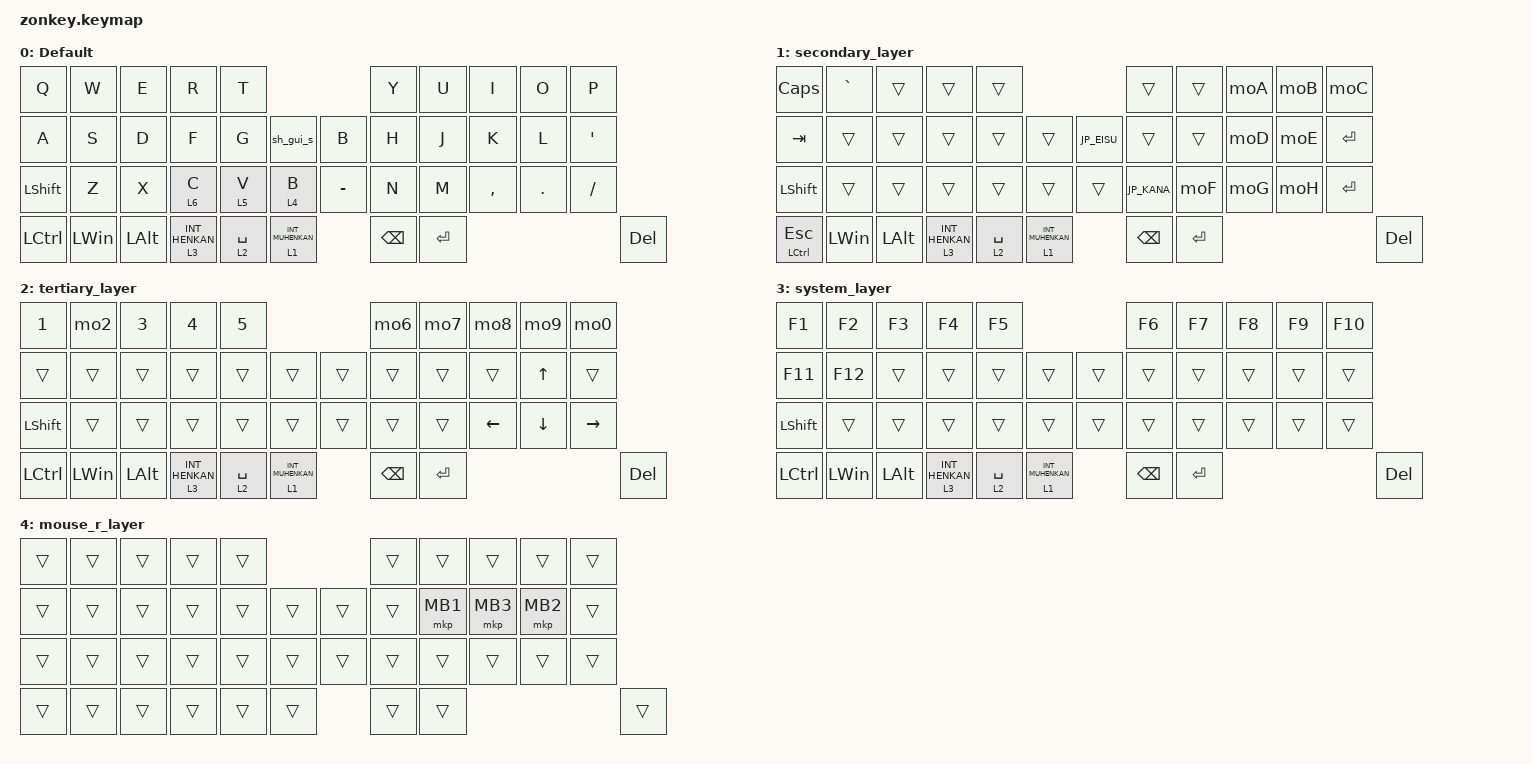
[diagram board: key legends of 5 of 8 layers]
#include <input/processors.dtsi>
#include <behaviors.dtsi>
#include <dt-bindings/zmk/bt.h>
#include <dt-bindings/zmk/keys.h>
#include <dt-bindings/zmk/outputs.h>
#include <dt-bindings/zmk/pointing.h>

#define DEFAULT_LAYER   0
#define SECONDARY_LAYER 1
#define TERTIARY_LAYER  2
#define SYSTEM_LAYER    3
#define MOUSE_R_LAYER   4
#define SCROLL_R_LAYER  5
#define MOUSE_L_LAYER   6
#define SCROLL_L_LAYER  7

// Mouse Scroll Value
#define ZMK_POINTING_DEFAULT_SCRL_VAL 100

// cirque trackpad input&layer control
&glidepoint_listener_R {
    input-processors =
        <&zip_xy_transform (INPUT_TRANSFORM_XY_SWAP | INPUT_TRANSFORM_X_INVERT | INPUT_TRANSFORM_Y_INVERT)>,
        <&zip_xy_scaler 3 2>,
        <&zip_temp_layer MOUSE_R_LAYER 300>;

    lowspeedmode {
        layers = <SECONDARY_LAYER>;
        input-processors =
            <&zip_xy_transform (INPUT_TRANSFORM_XY_SWAP | INPUT_TRANSFORM_X_INVERT | INPUT_TRANSFORM_Y_INVERT)>,
            <&zip_xy_scaler 3 5>,
            <&zip_temp_layer MOUSE_R_LAYER 300>;
    };

    scroller {
        layers = <SCROLL_R_LAYER>;
        input-processors =
            <&zip_xy_to_scroll_mapper>,
            <&zip_scroll_transform (INPUT_TRANSFORM_XY_SWAP | INPUT_TRANSFORM_Y_INVERT)>,
            <&zip_scroll_scaler 1 32>;
    };
};

&glidepoint_listener_L {
    input-processors =
        <&zip_xy_transform (INPUT_TRANSFORM_XY_SWAP | INPUT_TRANSFORM_X_INVERT | INPUT_TRANSFORM_Y_INVERT)>,
        <&zip_xy_scaler 3 2>,
        <&zip_temp_layer MOUSE_L_LAYER 300>;

    lowspeedmode {
        layers = <TERTIARY_LAYER>;
        input-processors =
            <&zip_xy_transform (INPUT_TRANSFORM_XY_SWAP | INPUT_TRANSFORM_X_INVERT | INPUT_TRANSFORM_Y_INVERT)>,
            <&zip_xy_scaler 3 4>,
            <&zip_temp_layer MOUSE_L_LAYER 300>;
    };

    scroller {
        layers = <SCROLL_L_LAYER>;
        input-processors =
            <&zip_xy_to_scroll_mapper>,
            <&zip_scroll_transform (INPUT_TRANSFORM_XY_SWAP | INPUT_TRANSFORM_Y_INVERT)>,
            <&zip_scroll_scaler 1 32>;
    };
};

&mt { quick-tap-ms = <200>; };

&lt { quick-tap-ms = <200>; };

/ {
    behaviors {
        // Encoder to Mouse Scroll

        scroll_up_down: behavior_sensor_rotate_mouse_wheel_up_down {
            compatible = "zmk,behavior-sensor-rotate";
            #sensor-binding-cells = <0>;
            bindings = <&msc SCRL_UP>, <&msc SCRL_DOWN>;

            tap-ms = <20>;
        };

        scroll_down_up: behavior_sensor_rotate_mouse_wheel_down_up {
            compatible = "zmk,behavior-sensor-rotate";
            #sensor-binding-cells = <0>;
            bindings = <&msc SCRL_DOWN>, <&msc SCRL_UP>;

            tap-ms = <20>;
        };

        scroll_left_right: behavior_sensor_rotate_mouse_wheel_left_right {
            compatible = "zmk,behavior-sensor-rotate";
            #sensor-binding-cells = <0>;
            bindings = <&msc SCRL_LEFT>, <&msc SCRL_RIGHT>;

            tap-ms = <20>;
        };

        scroll_right_left: behavior_sensor_rotate_mouse_wheel_right_left {
            compatible = "zmk,behavior-sensor-rotate";
            #sensor-binding-cells = <0>;
            bindings = <&msc SCRL_RIGHT>, <&msc SCRL_LEFT>;

            tap-ms = <20>;
        };

        volume_up_down: behavior_sensor_rotate_volume_up_down {
            compatible = "zmk,behavior-sensor-rotate";
            #sensor-binding-cells = <0>;
            bindings = <&kp C_VOLUME_UP>, <&kp C_VOLUME_DOWN>;

            tap-ms = <20>;
        };

        mt2: mod_tap2 {
            compatible = "zmk,behavior-hold-tap";
            #binding-cells = <2>;
            flavor = "tap-preferred";
            tapping-term-ms = <200>;
            quick-tap-ms = <200>;
            require-prior-idle-ms = <125>;
            bindings = <&kp>, <&kp>;
        };

        tap_dance_layer_1and2: tap_dance_layer_1and2 {
            compatible = "zmk,behavior-tap-dance";
            label = "td_mo12";
            #binding-cells = <0>;
            bindings = <&mo 1>, <&mo 2>;
        };
    };

    combos {
        compatible = "zmk,combos";

mo2: mo2 {
    compatible = "zmk,behavior-mod-morph";
    #binding-cells = <0>;
    bindings = <&kp N2>, <&kp AT>;
    mods = <MOD_LSFT MOD_RSFT>;
};

mo6: mo6 {
    compatible = "zmk,behavior-mod-morph";
    #binding-cells = <0>;
    bindings = <&kp N6>, <&kp CARET>;
    mods = <MOD_LSFT MOD_RSFT>;
};

    mo7: mo7 {
        compatible = "zmk,behavior-mod-morph";
        #binding-cells = <0>;
        bindings = <&kp N7>, <&kp AMPS>;

        mods = <(MOD_LSFT MOD_RSFT)>;
    };

    mo8: mo8 {
        compatible = "zmk,behavior-mod-morph";
        #binding-cells = <0>;
        bindings = <&kp N8>, <&kp ASTRK>;

        mods = <(MOD_LSFT MOD_RSFT)>;
    };

    mo9: mo9 {
        compatible = "zmk,behavior-mod-morph";
        #binding-cells = <0>;
        bindings = <&kp N9>, <&kp LPAR>;

        mods = <(MOD_LSFT MOD_RSFT)>;
    };

    mo0: mo0 {
        compatible = "zmk,behavior-mod-morph";
        #binding-cells = <0>;
        bindings = <&kp N0>, <&kp LPAR>;

        mods = <(MOD_LSFT MOD_RSFT)>;
    };

    moA: moA {
        compatible = "zmk,behavior-mod-morph";
        #binding-cells = <0>;
        bindings = <&kp MINUS>, <&kp UNDERSCORE>;

        mods = <(MOD_LSFT MOD_RSFT)>;
    };

    moB: moB {
        compatible = "zmk,behavior-mod-morph";
        #binding-cells = <0>;
        bindings = <&kp EQUAL>, <&kp PLUS>;

        mods = <(MOD_LSFT MOD_RSFT)>;
    };

    moC: moC {
        compatible = "zmk,behavior-mod-morph";
        #binding-cells = <0>;
        bindings = <&kp INT3>, <&kp JP_PIPE>;

        mods = <(MOD_LSFT MOD_RSFT)>;
    };

    moD: moD {
        compatible = "zmk,behavior-mod-morph";
        #binding-cells = <0>;
        bindings = <&kp LBKT>, <&kp LBRC>;

        mods = <(MOD_LSFT MOD_RSFT)>;
    };

    moE: moE {
        compatible = "zmk,behavior-mod-morph";
        #binding-cells = <0>;
        bindings = <&kp RBKT>, <&kp RBRC>;

        mods = <(MOD_LSFT MOD_RSFT)>;
    };

    moF: moF {
        compatible = "zmk,behavior-mod-morph";
        #binding-cells = <0>;
        bindings = <&kp SEMI>, <&kp KP_PLUS>;

        mods = <(MOD_LSFT MOD_RSFT)>;
    };

    moG: moG {
        compatible = "zmk,behavior-mod-morph";
        #binding-cells = <0>;
        bindings = <&kp APOSTROPHE>, <&kp DQT>;

        mods = <(MOD_LSFT MOD_RSFT)>;
    };

    moH: moH {
        compatible = "zmk,behavior-mod-morph";
        #binding-cells = <0>;
        bindings = <&kp BACKSLASH>, <&kp TILDE2>;

        mods = <(MOD_LSFT MOD_RSFT)>;
    };

    moI: moI {
        compatible = "zmk,behavior-mod-morph";
        #binding-cells = <0>;
        bindings = <&kp JP_BSLH>, <&kp JP_UNDERSCORE>;

        mods = <(MOD_LSFT MOD_RSFT)>;
    };

sh_gui_s: sh_gui_s {
        compatible = "zmk,behavior-macro";
        #binding-cells = <0>;
        bindings = <
            &kp LEFT_SHIFT
            &kp LEFT_WIN
            &kp S
        >;
    };


CONBO_ESC {
            bindings = <&kp ESCAPE>;
            key-positions = <0 1>;
        };

        COMBO_TAB {
            bindings = <&kp TAB>;
            key-positions = <10 11>;
        };

        COMBO_WIN {
            bindings = <&kp LWIN>;
            key-positions = <30 31>;
        };
    };

    macros {
        MACRO_LTAP: MACRO_LTAP {
            compatible = "zmk,behavior-macro";
            #binding-cells = <0>;
            bindings = <&mkp LCLK>;
            label = "MACRO_LTAP";
        };
    };

    keymap {
        compatible = "zmk,keymap";

        DEFAULT_LAYER {
            display-name = "Default";
            sensor-bindings = <&scroll_down_up>, <&scroll_up_down>;

             bindings = <
&kp Q           &kp W         &kp E         &kp R             &kp T                                         &kp Y          &kp U      &kp I      &kp O    &kp P
&kp A           &kp S         &kp D         &kp F             &kp G        &sh_gui_s         &kp B      &kp H          &kp J      &kp K      &kp L    &kp SQT
&kp LEFT_SHIFT  &kp Z         &kp X         &lt 6 C           &lt 5 V      &lt 4 B               &kp MINUS  &kp N          &kp M      &kp COMMA  &kp DOT  &kp SLASH
&kp LCTRL       &kp LEFT_WIN  &kp LEFT_ALT  &lt 3 INT_HENKAN  &lt 2 SPACE  &lt 1 INT_MUHENKAN               &kp BACKSPACE  &kp ENTER                                 &kp DEL
            >;
        };

        SECONDARY_LAYER {
            display-name = "secondary_layer";
            sensor-bindings = <&scroll_left_right>, <&scroll_left_right>;

            bindings = <
&kp CAPSLOCK    &kp GRAVE     &trans        &trans            &trans                                          &trans         &trans     &moA  &moB  &moC
&kp TAB         &trans        &trans        &trans            &trans       &trans                &kp JP_EISU  &trans         &trans     &moD  &moE  &kp ENTER
&kp LEFT_SHIFT  &trans        &trans        &trans            &trans       &trans                &trans       &kp JP_KANA    &moF       &moG  &moH  &kp ENTER
&mt LCTL ESC    &kp LEFT_WIN  &kp LEFT_ALT  &lt 3 INT_HENKAN  &lt 2 SPACE  &lt 1 INT_MUHENKAN                 &kp BACKSPACE  &kp ENTER                         &kp DEL
            >;
        };

        TERTIARY_LAYER {
            display-name = "tertiary_layer";
            bindings = <
&kp N1          &mo2          &kp N3        &kp N4            &kp N5                             &mo6    &mo7           &mo8       &mo9            &mo0
&trans          &trans        &trans        &trans            &trans       &trans                &trans  &trans         &trans     &trans          &kp UP_ARROW    &trans
&kp LEFT_SHIFT  &trans        &trans        &trans            &trans       &trans                &trans  &trans         &trans     &kp LEFT_ARROW  &kp DOWN_ARROW  &kp RIGHT_ARROW
&kp LCTRL       &kp LEFT_WIN  &kp LEFT_ALT  &lt 3 INT_HENKAN  &lt 2 SPACE  &lt 1 INT_MUHENKAN            &kp BACKSPACE  &kp ENTER                                                   &kp DEL
            >;

            sensor-bindings = <&scroll_left_right>, <&scroll_left_right>;
        };

        SYSTEM_LAYER {
            display-name = "system_layer";
            sensor-bindings = <&volume_up_down>, <&volume_up_down>;

            bindings = <
&kp F1          &kp F2        &kp F3        &kp F4            &kp F5                                     &kp F6         &kp F7     &kp F8  &kp F9  &kp F10
&kp F11         &kp F12       &trans        &trans            &trans       &trans                &trans  &trans         &trans     &trans  &trans  &trans
&kp LEFT_SHIFT  &trans        &trans        &trans            &trans       &trans                &trans  &trans         &trans     &trans  &trans  &trans
&kp LCTRL       &kp LEFT_WIN  &kp LEFT_ALT  &lt 3 INT_HENKAN  &lt 2 SPACE  &lt 1 INT_MUHENKAN            &kp BACKSPACE  &kp ENTER                           &kp DEL
            >;
        };

        MOUSE_R_LAYER {
            display-name = "mouse_r_layer";
            bindings = <
&trans  &trans  &trans  &trans  &trans                    &trans  &trans    &trans    &trans    &trans
&trans  &trans  &trans  &trans  &trans  &trans    &trans  &trans  &mkp MB1  &mkp MB3  &mkp MB2  &trans
&trans  &trans  &trans  &trans  &trans  &trans    &trans  &trans  &trans    &trans    &trans    &trans
&trans  &trans  &trans  &trans  &trans  &trans            &trans  &trans                                &trans
            >;
        };

        SCROLL_R_LAYER {
            display-name = "scroll_r_layer";
            bindings = <
&trans  &trans  &trans  &trans  &trans  &trans  &trans  &trans  &trans  &trans
&trans  &trans  &trans  &trans  &trans  &trans  &trans  &trans  &trans  &trans
&trans  &trans  &trans  &trans  &trans  &trans  &trans  &trans  &trans  &trans
&trans  &trans          &trans  &trans  &trans  &trans          &trans  &trans
            >;
        };

        MOUSE_L_LAYER {
            display-name = "mouse_l_layer";
            bindings = <
&trans  &trans       &mkp MCLK  &trans     &trans  &trans  &trans  &trans  &trans  &trans
&mo 7   &MACRO_LTAP  &mkp LCLK  &mkp RCLK  &trans  &trans  &trans  &trans  &trans  &trans
&trans  &mkp MB4     &trans     &mkp MB5   &trans  &trans  &trans  &trans  &trans  &trans
&trans  &trans                  &trans     &trans  &trans  &trans          &trans  &trans
            >;
        };

        SCROLL_L_LAYER {
            display-name = "scroll_l_layer";
            bindings = <
&trans  &trans  &trans  &trans  &trans  &trans  &trans  &trans  &trans  &trans
&trans  &trans  &trans  &trans  &trans  &trans  &trans  &trans  &trans  &trans
&trans  &trans  &trans  &trans  &trans  &trans  &trans  &trans  &trans  &trans
&trans  &trans          &trans  &trans  &trans  &trans          &trans  &trans
            >;
        };
    };

    conditional_layers {
        compatible = "zmk,conditional-layers";

        System_layer {
            if-layers = <1 2>;
            then-layer = <3>;
        };
    };
};
